# TC37X register map
File version: 1.0.0
CPU: CM4 r0p1, little endian, MPU, FPU, VTOR, 3 interrupt priority bits
Registers are 16-bit, read-write, reset 0x0 unless marked. A register's access mark holds for its fields unless they carry their own. Offsets are from the block's base; [hi:lo] are bit positions; {n}, {i} and the like mark numbered series; 'fields as' and 'values as' point back to an identical list.

## STM0 — ce_stm
Base 0xF0001000
Same registers: STM1 0xF0001100, STM2 0xF0001200
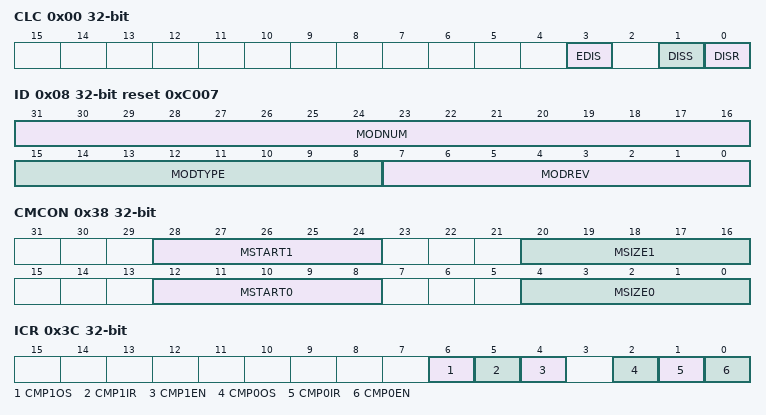
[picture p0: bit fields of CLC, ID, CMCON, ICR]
0x00 CLC 32-bit — Clock Control Register
  [3] EDIS — Sleep Mode Enable Control - EDIS
  [1] DISS ro — Module Disable Status Bit - DISS
  [0] DISR — Module Disable Request Bit - DISR
0x08 ID 32-bit ro reset 0xC007 — Module Identification Register
  [31:16] MODNUM — Module Number Value - MODNUM
  [15:8] MODTYPE — Module Type - MODTYPE
  [7:0] MODREV — Module Revision Number - MODREV
{0x10+4i} TIM{i} 32-bit ro (i=0..5) — Timer Register {i}
  [31:0] STM_{4i+31}_{4i} — System Timer Bits [{4i+31}:{4i}] - STM[{4i+31}:{4i}]
0x28 TIM6 32-bit ro — Timer Register 6
  [31:0] STM_63_32 — System Timer Bits [63:32] - STM[63:32]
0x2C CAP 32-bit ro — Timer Capture Register
  [31:0] STMCAP_63_32 — Captured System Timer Bits [63:32] - STMCAP[63:32]
0x30 CMP0 32-bit — Compare Register 0
  [31:0] CMPVAL — Compare Value of Compare Register x - CMPVAL
0x34 CMP1 32-bit — Compare Register 1
  [31:0] CMPVAL — Compare Value of Compare Register x - CMPVAL
0x38 CMCON 32-bit — Compare Match Control Register
  [28:24] MSTART1 — Start Bit Location for CMP1 - MSTART1
  [20:16] MSIZE1 — Compare Register Size for CMP1 - MSIZE1
  [12:8] MSTART0 — Start Bit Location for CMP0 - MSTART0
  [4:0] MSIZE0 — Compare Register Size for CMP0 - MSIZE0
0x3C ICR 32-bit — Interrupt Control Register
  [6] CMP1OS — Compare Register CMP1 Interrupt Output Selection - CMP1OS
  [5] CMP1IR ro — Compare Register CMP1 Interrupt Request Flag - CMP1IR
  [4] CMP1EN — Compare Register CMP1 Interrupt Enable Control - CMP1EN
  [2] CMP0OS — Compare Register CMP0 Interrupt Output Selection - CMP0OS
  [1] CMP0IR ro — Compare Register CMP0 Interrupt Request Flag - CMP0IR
  [0] CMP0EN — Compare Register CMP0 Interrupt Enable Control - CMP0EN
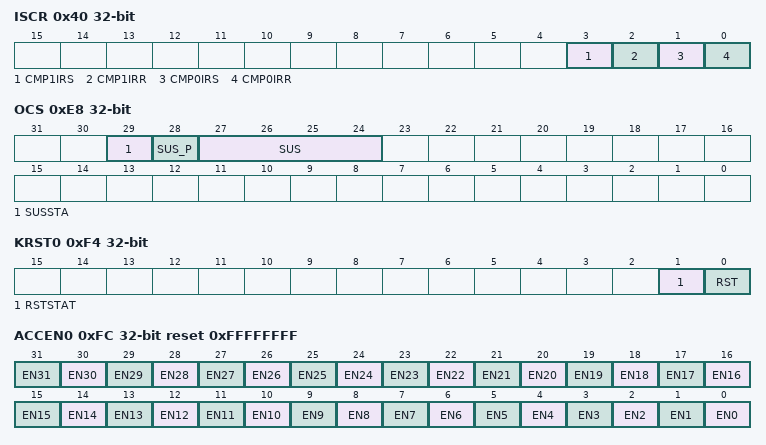
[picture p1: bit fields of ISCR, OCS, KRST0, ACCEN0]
0x40 ISCR 32-bit wo — Interrupt Set/Clear Register
  [3] CMP1IRS — Set Compare Register CMP1 Interrupt Flag - CMP1IRS
  [2] CMP1IRR — Reset Compare Register CMP1 Interrupt Flag - CMP1IRR
  [1] CMP0IRS — Set Compare Register CMP0 Interrupt Flag - CMP0IRS
  [0] CMP0IRR — Reset Compare Register CMP0 Interrupt Flag - CMP0IRR
0x50 TIM0SV 32-bit ro — Timer Register 0 Second View
  [31:0] STM_31_0 — System Timer Bits [31:0] - STM[31:0]
0x54 CAPSV 32-bit ro — Timer Capture Register Second View
  fields as CAP
0xE8 OCS 32-bit — OCDS Control and Status Register
  [29] SUSSTA ro — Suspend State - SUSSTA
  [28] SUS_P wo — SUS Write Protection - SUS_P
  [27:24] SUS — OCDS Suspend Control - SUS
0xEC KRSTCLR 32-bit wo — Kernel Reset Status Clear Register
  [0] CLR — Kernel Reset Status Clear - CLR
0xF0 KRST1 32-bit — Kernel Reset Register 1
  [0] RST — Kernel Reset - RST
0xF4 KRST0 32-bit — Kernel Reset Register 0
  [1] RSTSTAT ro — Kernel Reset Status - RSTSTAT
  [0] RST — Kernel Reset - RST
0xF8 ACCEN1 32-bit ro — Access Enable Register 1
0xFC ACCEN0 32-bit reset 0xFFFFFFFF — Access Enable Register 0
  [n] EN{n} (n=0..31) — Access Enable for Master TAG ID {n} - EN{n}

## port_00 — eneral Purpose I/O Ports and Peripheral I/O Lines
Base 0xF003A000
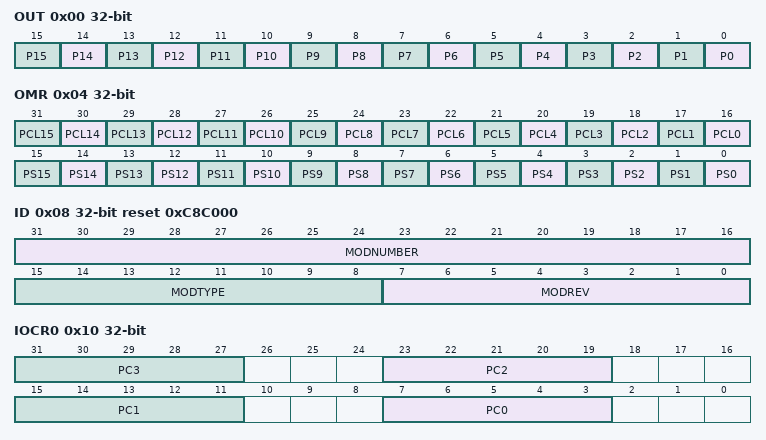
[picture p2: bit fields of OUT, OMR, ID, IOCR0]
0x00 OUT 32-bit — Port 00 Output Register
  [n] P{n} (n=0..15) — Output Bit {n}
0x04 OMR 32-bit wo — Port 00 Output Modification Register
  [n+16] PCL{n} (n=0..15) — Clear Bit {n}
  [n] PS{n} (n=0..15) — Set Bit {n}
0x08 ID 32-bit ro reset 0xC8C000 (reset mask 0xFFFFFF00) — Port 00 Identification Register
  [31:16] MODNUMBER — Module Number
  [15:8] MODTYPE — Module Type
  [7:0] MODREV — Module Revision Number
0x10 IOCR0 32-bit — Port 00 Input/Output Control Register 0
  [8n+7:8n+3] PC{n} (n=0..3) — Port Control for Pin {n}
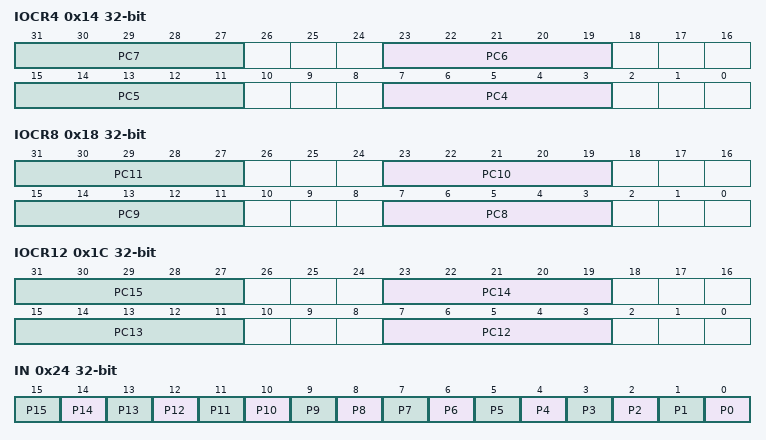
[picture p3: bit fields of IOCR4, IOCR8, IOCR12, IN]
0x14 IOCR4 32-bit — Port 00 Input/Output Control Register 4
  [8n-25:8n-29] PC{n} (n=4..7) — Port Control for Port 00 Pin {n}
0x18 IOCR8 32-bit — Port 00 Input/Output Control Register 8
  [8n-57:8n-61] PC{n} (n=8..11) — Port Control for Port 00 Pin {n}
0x1C IOCR12 32-bit — Port 00 Input/Output Control Register 12
  [8n-89:8n-93] PC{n} (n=12..15) — Port Control for Port 00 Pin {n}
0x24 IN 32-bit ro (reset mask 0xFFFF0000) — Port 00 Input Register
  [n] P{n} (n=0..15) — Input Bit {n}
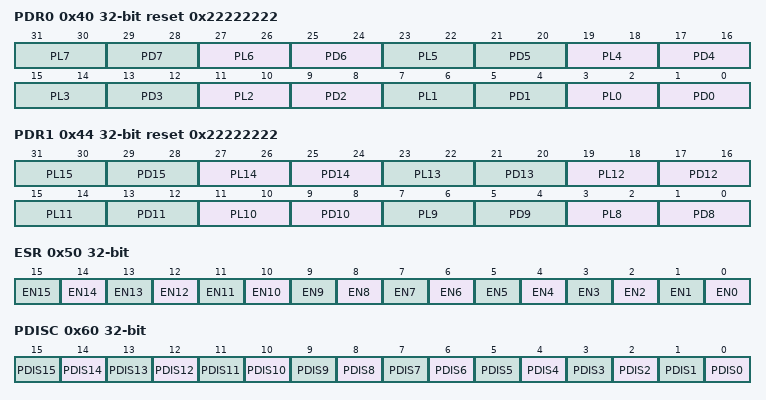
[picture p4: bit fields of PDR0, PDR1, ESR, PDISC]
0x40 PDR0 32-bit reset 0x22222222 — Port 00 Pad Driver Mode Register 0
  [4n+3:4n+2] PL{n} (n=0..7) — Pad Level Selection for Pin {n}
  [4n+1:4n] PD{n} (n=0..7) — Pad Driver Mode for Pin {n}
0x44 PDR1 32-bit reset 0x22222222 — Port 00 Pad Driver Mode Register 1
  [4n-29:4n-30] PL{n} (n=8..15) — Pad Level Selection for Pin {n}
  [4n-31:4n-32] PD{n} (n=8..15) — Pad Driver Mode for Pin {n}
0x50 ESR 32-bit — Port 00 Emergency Stop Register
  [n] EN{n} (n=0..15) — Emergency Stop Enable for Pin {n}
0x60 PDISC 32-bit — Port 00 Pin Function Decision Control Register
  [n] PDIS{n} (n=0..15) — Pin Function Decision Control for Pin {n}
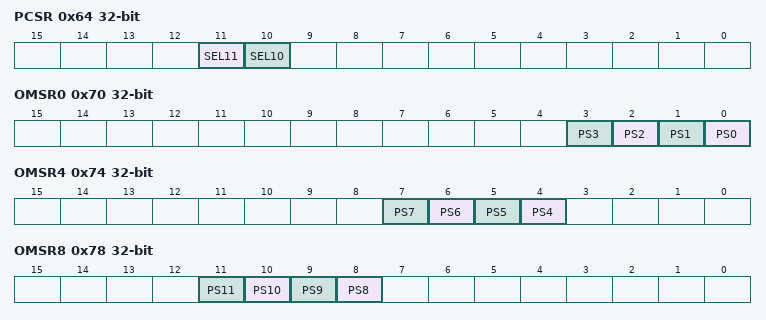
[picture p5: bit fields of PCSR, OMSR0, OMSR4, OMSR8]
0x64 PCSR 32-bit — Port 00 Pin Controller Select Register
  [11] SEL11 — Output Select for Pin 11
  [10] SEL10 — Output Select for Pin 10
0x70 OMSR0 32-bit — Port 00 Output Modification Set Register 0
  [n] PS{n} wo (n=0..3) — Set Bit {n}
0x74 OMSR4 32-bit — Port 00 Output Modification Set Register 4
  [n] PS{n} wo (n=4..7) — Set Bit {n}
0x78 OMSR8 32-bit — Port 00 Output Modification Set Register 8
  [n] PS{n} wo (n=8..11) — Set Bit {n}
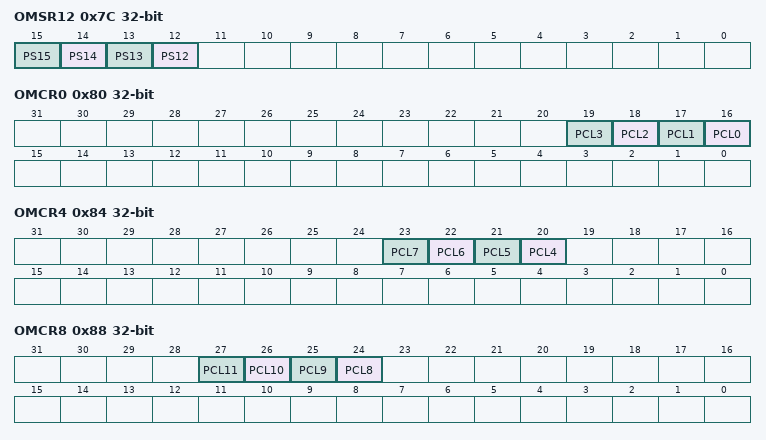
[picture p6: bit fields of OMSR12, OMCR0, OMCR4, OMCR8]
0x7C OMSR12 32-bit — Port 00 Output Modification Set Register 12
  [n] PS{n} wo (n=12..15) — Set Bit {n}
0x80 OMCR0 32-bit — Port 00 Output Modification Clear Register 0
  [n+16] PCL{n} wo (n=0..3) — Clear Bit {n}
0x84 OMCR4 32-bit — Port 00 Output Modification Clear Register 4
  [n+16] PCL{n} wo (n=4..7) — Clear Bit {n}
0x88 OMCR8 32-bit — Port 00 Output Modification Clear Register 8
  [n+16] PCL{n} wo (n=8..11) — Clear Bit {n}
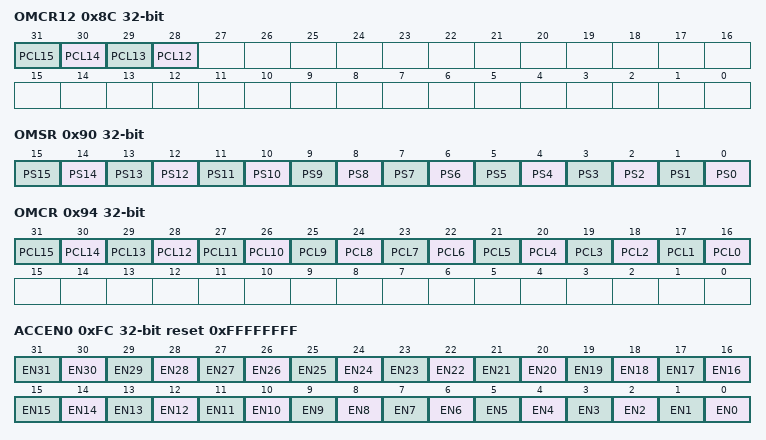
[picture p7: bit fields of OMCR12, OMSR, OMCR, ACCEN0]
0x8C OMCR12 32-bit — Port 00 Output Modification Clear Register 12
  [n+16] PCL{n} wo (n=12..15) — Clear Bit {n}
0x90 OMSR 32-bit — Port 00 Output Modification Set Register
  [n] PS{n} wo (n=0..15) — Set Bit {n}
0x94 OMCR 32-bit — Port 00 Output Modification Clear Register
  [n+16] PCL{n} wo (n=0..15) — Clear Bit {n}
0xF8 ACCEN1 32-bit ro — Port 00 Access Enable Register 1
0xFC ACCEN0 32-bit reset 0xFFFFFFFF — Port 00 Access Enable Register 0
  [n] EN{n} (n=0..31) — Access Enable for Master TAG ID {n}
